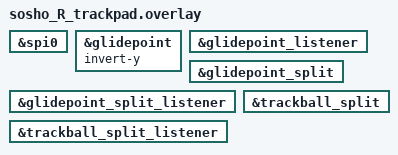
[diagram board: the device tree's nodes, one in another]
#include "sosho_R.dtsi"

&spi0 { status = "okay"; };
&glidepoint {
    status = "okay";
    invert-y;
};
&glidepoint_listener {
    status = "okay";
/* input-processors = <&zip_xy_scaler 2 1>; */
};

&glidepoint_split { status = "okay"; };
&glidepoint_split_listener {
    status = "okay";
/* input-processors = <&zip_xy_scaler 2 1>; */
};

&trackball_split { status = "okay"; };
&trackball_split_listener { status = "okay"; };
